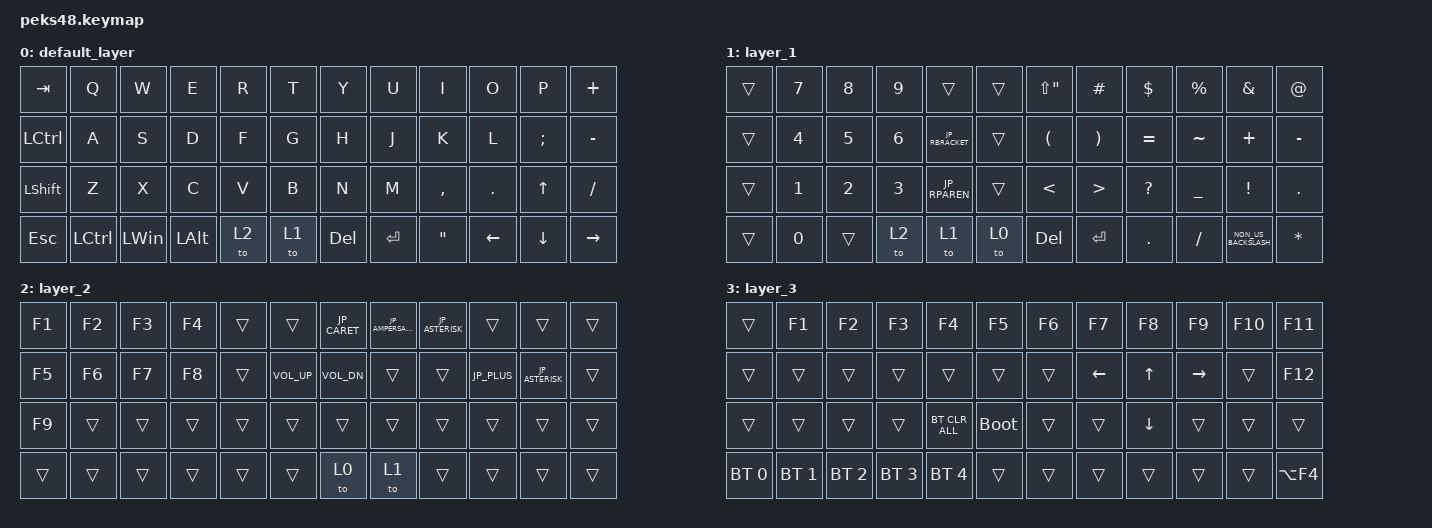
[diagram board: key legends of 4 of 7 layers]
#include <input/processors.dtsi>
#include <dt-bindings/zmk/input_transform.h>
#include <zephyr/dt-bindings/input/input-event-codes.h>
#include <behaviors.dtsi>
#include <dt-bindings/zmk/bt.h>
#include <dt-bindings/zmk/keys.h>
#include <dt-bindings/zmk/pointing.h>

// Conversion definition for using Japanese keyboard with OS settings

#define JP_DQUOTE       AT                // "
#define JP_AMPERSAND    CARET             // &
#define JP_QUOTE        AMPERSAND         // '
#define JP_EQUAL        UNDER             // =
#define JP_CARET        EQUAL             // ^
#define JP_YEN          0x89              // ¥
#define JP_PLUS         COLON             // +
#define JP_TILDE        PLUS              // ~
#define JP_PIPE         LS(0x89)          // |
#define JP_AT           LEFT_BRACKET      // @
#define JP_COLON        SINGLE_QUOTE      // :
#define JP_ASTERISK     DOUBLE_QUOTES     // *
#define JP_BACKQUOTE    LEFT_BRACE        // `
#define JP_UNDERSCORE   LS(0x87)          // _
#define JP_LBRACKET     RIGHT_BRACKET     // [
#define JP_RBRACKET     BACKSLASH         // ]
#define JP_LPAREN       ASTERISK          // (
#define JP_RPAREN       LEFT_PARENTHESIS  // )
#define JP_LBRACE       RIGHT_BRACE       // {
#define JP_RBRACE       PIPE              // }
#define JP_KANA         LANGUAGE_1        // かな
#define JP_EISU         LANGUAGE_2        // 英数
#define JP_HANZEN       GRAVE             // 半角/全角

&mt {
    flavor = "balanced";
    quick-tap-ms = <0>;
};

/ {
    keymap {
        compatible = "zmk,keymap";

        default_layer {
            bindings = <
&kp TAB         &kp Q             &kp W     &kp E     &kp R  &kp T    &kp Y    &kp U      &kp I              &kp O           &kp P           &kp PLUS
&kp LCTRL       &kp A             &kp S     &kp D     &kp F  &kp G    &kp H    &kp J      &kp K              &kp L           &kp SEMICOLON   &kp MINUS
&kp LEFT_SHIFT  &kp Z             &kp X     &kp C     &kp V  &kp B    &kp N    &kp M      &kp COMMA          &kp DOT         &kp UP_ARROW    &kp SLASH
&kp ESC         &kp LEFT_CONTROL  &kp LWIN  &kp LALT  &to 2  &to 1    &kp DEL  &kp ENTER  &kp DOUBLE_QUOTES  &kp LEFT_ARROW  &kp DOWN_ARROW  &kp RIGHT_ARROW
            >;
        };

        layer_1 {
            bindings = <
&trans  &kp NUMBER_7  &kp NUMBER_8  &kp NUMBER_9  &trans           &trans    &kp LS(DOUBLE_QUOTES)  &kp HASH               &kp DOLLAR    &kp PERCENT  &kp AMPERSAND         &kp AT_SIGN
&trans  &kp NUMBER_4  &kp NUMBER_5  &kp NUMBER_6  &kp JP_RBRACKET  &trans    &kp LEFT_PARENTHESIS   &kp RIGHT_PARENTHESIS  &kp EQUAL     &kp TILDE    &kp PLUS              &kp MINUS
&trans  &kp NUMBER_1  &kp NUMBER_2  &kp NUMBER_3  &kp JP_RPAREN    &trans    &kp LESS_THAN          &kp GREATER_THAN       &kp QUESTION  &kp UNDER    &kp EXCLAMATION       &kp PERIOD
&trans  &kp NUMBER_0  &trans        &to 2         &to 1            &to 0     &kp DELETE             &kp ENTER              &kp PERIOD    &kp SLASH    &kp NON_US_BACKSLASH  &kp ASTERISK
            >;
        };

        layer_2 {
            bindings = <
&kp F1  &kp F2  &kp F3  &kp F4  &trans  &trans          &kp JP_CARET  &kp JP_AMPERSAND  &kp JP_ASTERISK  &trans       &trans           &trans
&kp F5  &kp F6  &kp F7  &kp F8  &trans  &kp C_VOL_UP    &kp C_VOL_DN  &trans            &trans           &kp JP_PLUS  &kp JP_ASTERISK  &trans
&kp F9  &trans  &trans  &trans  &trans  &trans          &trans        &trans            &trans           &trans       &trans           &trans
&trans  &trans  &trans  &trans  &trans  &trans          &to 0         &to 1             &trans           &trans       &trans           &trans
            >;
        };

        layer_3 {
            bindings = <
&trans        &kp F1        &kp F2        &kp F3        &kp F4          &kp F5         &kp F6  &kp F7          &kp F8          &kp F9           &kp F10  &kp F11
&trans        &trans        &trans        &trans        &trans          &trans         &trans  &kp LEFT_ARROW  &kp UP_ARROW    &kp RIGHT_ARROW  &trans   &kp F12
&trans        &trans        &trans        &trans        &bt BT_CLR_ALL  &bootloader    &trans  &trans          &kp DOWN_ARROW  &trans           &trans   &trans
&bt BT_SEL 0  &bt BT_SEL 1  &bt BT_SEL 2  &bt BT_SEL 3  &bt BT_SEL 4    &trans         &trans  &trans          &trans          &trans           &trans   &kp LA(F4)
            >;
        };

        layer_4 {
            bindings = <
&trans  &trans  &trans  &trans  &trans  &trans    &trans       &bt BT_SEL 0  &bt BT_SEL 1  &bt BT_SEL 2  &bt BT_SEL 3  &bt BT_SEL 4
&trans  &trans  &trans  &trans  &trans  &trans    &trans       &tog 6        &trans        &trans        &trans        &bt BT_CLR
&trans  &trans  &trans  &trans  &trans  &trans    &bootloader  &trans        &trans        &trans        &trans        &bt BT_CLR_ALL
&trans  &trans  &trans  &trans
            >;
        };

        layer_5 {
            bindings = <
&trans  &trans  &trans    &trans    &trans    &trans    &trans  &trans    &trans    &trans    &trans  &trans
&trans  &trans  &mkp MB3  &mkp MB2  &mkp MB1  &trans    &trans  &mkp MB1  &mkp MB2  &mkp MB3  &trans  &trans
&trans  &trans  &trans    &trans    &trans    &trans    &trans  &trans    &trans    &trans    &trans  &trans
&trans  &trans  &trans    &trans
            >;
        };

        layer_6 {
            bindings = <
&trans  &trans  &trans  &trans  &trans  &trans    &trans  &trans  &trans    &trans    &trans    &trans
&trans  &trans  &trans  &trans  &trans  &trans    &trans  &trans  &mkp MB1  &mkp MB3  &mkp MB2  &trans
&trans  &trans  &trans  &trans  &trans  &trans    &trans  &trans  &trans    &trans    &trans    &trans
&trans  &trans  &trans  &trans
            >;
        };
    };
};
